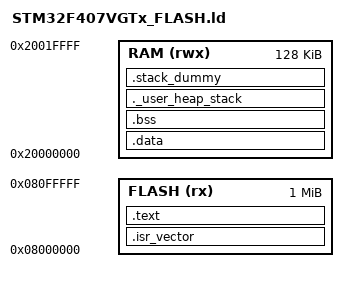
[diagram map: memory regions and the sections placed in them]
ENTRY(Reset_Handler)

MEMORY
{
  FLASH (rx) : ORIGIN = 0x08000000, LENGTH = 1024K
  RAM (rwx)  : ORIGIN = 0x20000000, LENGTH = 128K
}

SECTIONS
{
  .isr_vector :
  {
    . = ALIGN(4);
    KEEP(*(.isr_vector))
    . = ALIGN(4);
  } >FLASH

  .text :
  {
    . = ALIGN(4);
    *(.text)
    *(.text*)
    *(.rodata)
    *(.rodata*)
    . = ALIGN(4);
  } >FLASH

  . = ALIGN(4);
  _etext = .;
  _sidata = LOADADDR(.data);

  .data : AT (_etext)
  {
    . = ALIGN(4);
    _sdata = .;
    *(.data)
    *(.data*)
    . = ALIGN(4);
    _edata = .;
  } >RAM

  .bss :
  {
    . = ALIGN(4);
    _sbss = .;
    *(.bss)
    *(.bss*)
    *(COMMON)
    . = ALIGN(4);
    _ebss = .;
  } >RAM

  ._user_heap_stack :
  {
    . = ALIGN(8);
    PROVIDE ( end = . );
    PROVIDE ( _end = . );
    . = . + 0x2000;  /* 8KB heap */
    . = ALIGN(8);
    __HeapLimit = .;
  } >RAM

  /* .stack_dummy section doesn't contains any symbols. It is only
   * used for linker to calculate size of stack sections, and assign
   * values to stack symbols later */
  .stack_dummy (COPY):
  {
    . = ALIGN(8);
    *(.stack*)
  } >RAM

  /* Set stack top to end of RAM, and stack limit move from end of
   * RAM by amount of stack_dummy section size. */
  __StackTop = ORIGIN(RAM) + LENGTH(RAM);
  __StackLimit = __StackTop - SIZEOF(.stack_dummy);
  PROVIDE(_estack = __StackTop);

  /* Check if data + heap + stack exceeds RAM limit */
  ASSERT(__StackLimit >= __HeapLimit, "region RAM overflowed with stack")
}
